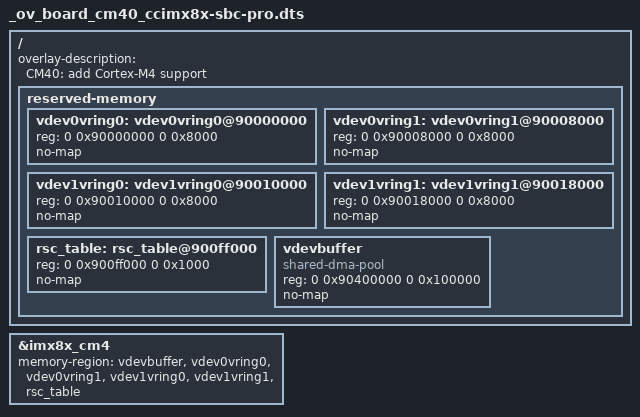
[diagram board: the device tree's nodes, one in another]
/*
 * Copyright 2023 Digi International Inc.
 *
 * Permission to use, copy, modify, and/or distribute this software for any
 * purpose with or without fee is hereby granted, provided that the above
 * copyright notice and this permission notice appear in all copies.
 * THE SOFTWARE IS PROVIDED "AS IS" AND THE AUTHOR DISCLAIMS ALL WARRANTIES
 * WITH REGARD TO THIS SOFTWARE INCLUDING ALL IMPLIED WARRANTIES OF
 * MERCHANTABILITY AND FITNESS. IN NO EVENT SHALL THE AUTHOR BE LIABLE FOR
 * ANY SPECIAL, DIRECT, INDIRECT, OR CONSEQUENTIAL DAMAGES OR ANY DAMAGES
 * WHATSOEVER RESULTING FROM LOSS OF USE, DATA OR PROFITS, WHETHER IN AN
 * ACTION OF CONTRACT, NEGLIGENCE OR OTHER TORTIOUS ACTION, ARISING OUT OF
 * OR IN CONNECTION WITH THE USE OR PERFORMANCE OF THIS SOFTWARE.
 */

/dts-v1/;
/plugin/;

/ {
	fragment@0 {
		target-path = "/";
		__overlay__ {
			overlay-description = "CM40: add Cortex-M4 support";
			reserved-memory {
				vdev0vring0: vdev0vring0@90000000 {
					reg = <0 0x90000000 0 0x8000>;
					no-map;
				};

				vdev0vring1: vdev0vring1@90008000 {
					reg = <0 0x90008000 0 0x8000>;
					no-map;
				};

				vdev1vring0: vdev1vring0@90010000 {
					reg = <0 0x90010000 0 0x8000>;
					no-map;
				};

				vdev1vring1: vdev1vring1@90018000 {
					reg = <0 0x90018000 0 0x8000>;
					no-map;
				};

				rsc_table: rsc_table@900ff000 {
					reg = <0 0x900ff000 0 0x1000>;
					no-map;
				};

				vdevbuffer: vdevbuffer {
					compatible = "shared-dma-pool";
					reg = <0 0x90400000 0 0x100000>;
					no-map;
				};
			};
		};
	};

	fragment@1 {
		target = <&imx8x_cm4>;
		__overlay__ {
			memory-region = <&vdevbuffer>, <&vdev0vring0>, <&vdev0vring1>,
				<&vdev1vring0>, <&vdev1vring1>, <&rsc_table>;
			status = "okay";
		};
	};
};
